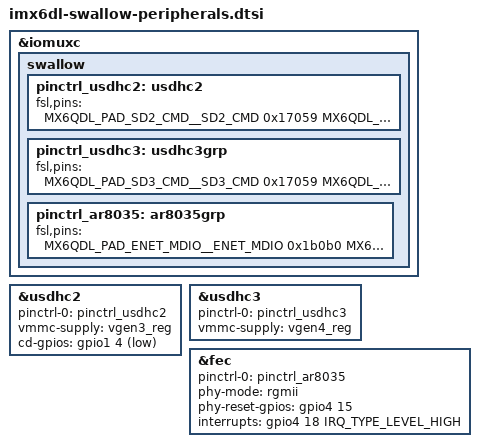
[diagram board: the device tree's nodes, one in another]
/* This dts is for the optional devices we may add, hence kept separately
* 
*/



&iomuxc {
	swallow {
		pinctrl_usdhc2: usdhc2 {
		fsl,pins = <
			MX6QDL_PAD_SD2_CMD__SD2_CMD		0x17059
			MX6QDL_PAD_SD2_CLK__SD2_CLK		0x10059
			MX6QDL_PAD_SD2_DAT0__SD2_DATA0		0x17059
			MX6QDL_PAD_SD2_DAT1__SD2_DATA1		0x17059
			MX6QDL_PAD_SD2_DAT2__SD2_DATA2		0x17059
			MX6QDL_PAD_SD2_DAT3__SD2_DATA3		0x17059
			>;
		};
		
		pinctrl_usdhc3: usdhc3grp {
		fsl,pins = <
			MX6QDL_PAD_SD3_CMD__SD3_CMD		0x17059
			MX6QDL_PAD_SD3_CLK__SD3_CLK		0x10059
			MX6QDL_PAD_SD3_DAT0__SD3_DATA0		0x17059
			MX6QDL_PAD_SD3_DAT1__SD3_DATA1		0x17059
			MX6QDL_PAD_SD3_DAT2__SD3_DATA2		0x17059
			MX6QDL_PAD_SD3_DAT3__SD3_DATA3		0x17059
			MX6QDL_PAD_SD3_DAT4__SD3_DATA4		0x17059
			MX6QDL_PAD_SD3_DAT5__SD3_DATA5		0x17059
			MX6QDL_PAD_SD3_DAT6__SD3_DATA6		0x17059
			MX6QDL_PAD_SD3_DAT7__SD3_DATA7		0x17059
			MX6QDL_PAD_SD3_RST__SD3_RESET		0x17059
			>;
		};
		pinctrl_ar8035: ar8035grp {
			fsl,pins = <
				MX6QDL_PAD_ENET_MDIO__ENET_MDIO		0x1b0b0
				MX6QDL_PAD_ENET_MDC__ENET_MDC		0x1b0b0
				MX6QDL_PAD_KEY_ROW4__GPIO4_IO15		0x130b0		/* AR8035 reset */
				MX6QDL_PAD_DI0_PIN2__GPIO4_IO18		0x80000000	/* AR8035 interrupt */
				MX6QDL_PAD_GPIO_16__ENET_REF_CLK	0x4001b0a8	/* GPIO16 --> AR8035 25MHz */
				MX6QDL_PAD_RGMII_TXC__RGMII_TXC		0x1b0b0
				MX6QDL_PAD_RGMII_TD0__RGMII_TD0		0x1b0b0
				MX6QDL_PAD_RGMII_TD1__RGMII_TD1		0x1b0b0
				MX6QDL_PAD_RGMII_TD2__RGMII_TD2		0x1b0b0
				MX6QDL_PAD_RGMII_TD3__RGMII_TD3		0x1b0b0
				MX6QDL_PAD_RGMII_TX_CTL__RGMII_TX_CTL	0x1b0b0
				MX6QDL_PAD_ENET_REF_CLK__ENET_TX_CLK	0x0a0b1	/* AR8035 CLK_25M --> ENET_REF_CLK (V22) */
				MX6QDL_PAD_RGMII_RXC__RGMII_RXC		0x1b0b0
				MX6QDL_PAD_RGMII_RD0__RGMII_RD0		0x130b0	
				MX6QDL_PAD_RGMII_RD1__RGMII_RD1		0x130b0	
				MX6QDL_PAD_RGMII_RD2__RGMII_RD2		0x1b0b0
				MX6QDL_PAD_RGMII_RD3__RGMII_RD3		0x1b0b0
				MX6QDL_PAD_RGMII_RX_CTL__RGMII_RX_CTL	0x130b0	
				>;
			};
	}; // swallow
};

&usdhc2 {
	pinctrl-names = "default";
	pinctrl-0 = <&pinctrl_usdhc2>;
	vmmc-supply = <&vgen3_reg>;
	cd-gpios = <&gpio1 4 GPIO_ACTIVE_LOW>;
	status = "okay";
};

&usdhc3 {
	pinctrl-names = "default";
	pinctrl-0 = <&pinctrl_usdhc3>;
	vmmc-supply = <&vgen4_reg>;
	status = "okay";
};

&fec  {
	pinctrl-names = "default";
	pinctrl-0 = <&pinctrl_ar8035>;
	phy-mode = "rgmii";
	phy-reset-gpios = <&gpio4 15 0>;
	interrupts = <&gpio4 18 IRQ_TYPE_LEVEL_HIGH>;
	status = "okay";
};
